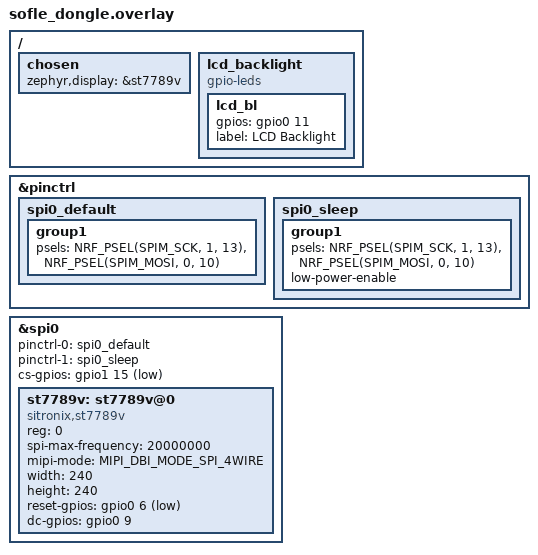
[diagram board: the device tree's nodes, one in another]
/*
 * Dongle Screen - ST7789 1.54" TFT SPI
 * Board: nice!nano / Pro Micro nRF52840
 *
 * Pinout:
 *   SCLK  -> P1.13 (D15)
 *   MOSI  -> P0.10 (D16)
 *   CS    -> P1.15 (D18)
 *   DC    -> P0.09 (D10)
 *   RST   -> P0.06 (D1)
 *   BL    -> P0.11 (D7)
 *   VCC   -> 3.3V
 *   GND   -> GND
 */

#include <zephyr/dt-bindings/gpio/gpio.h>
#include <zephyr/dt-bindings/mipi_dbi/mipi_dbi.h>

/ {
    chosen {
        zephyr,display = &st7789v;
    };

    /* Backlight como LED GPIO */
    lcd_backlight: lcd_backlight {
        compatible = "gpio-leds";
        lcd_bl: lcd_bl {
            gpios = <&gpio0 11 GPIO_ACTIVE_HIGH>;
            label = "LCD Backlight";
        };
    };
};

/* Configuración de pines SPI0 para nRF52840 */
&pinctrl {
    spi0_default: spi0_default {
        group1 {
            psels = <NRF_PSEL(SPIM_SCK, 1, 13)>,
                    <NRF_PSEL(SPIM_MOSI, 0, 10)>;
        };
    };

    spi0_sleep: spi0_sleep {
        group1 {
            psels = <NRF_PSEL(SPIM_SCK, 1, 13)>,
                    <NRF_PSEL(SPIM_MOSI, 0, 10)>;
            low-power-enable;
        };
    };
};

&spi0 {
    status = "okay";
    pinctrl-0 = <&spi0_default>;
    pinctrl-1 = <&spi0_sleep>;
    pinctrl-names = "default", "sleep";

    cs-gpios = <&gpio1 15 GPIO_ACTIVE_LOW>; /* CS en P1.15 */

    st7789v: st7789v@0 {
        compatible = "sitronix,st7789v";
        reg = <0>;
        spi-max-frequency = <20000000>;

        /* Requerido por Zephyr 4.1 */
        mipi-mode = "MIPI_DBI_MODE_SPI_4WIRE";

        /* Dimensiones de la pantalla */
        width = <240>;
        height = <240>;

        /* Pines de control */
        reset-gpios = <&gpio0 6 GPIO_ACTIVE_LOW>;   /* RST en P0.06 */
        dc-gpios    = <&gpio0 9 GPIO_ACTIVE_HIGH>;  /* DC  en P0.09 */

        /*
         * Si los colores salen invertidos (rojo <-> azul),
         * prueba a añadir una de estas líneas:
         *
         *   inversion-off;
         *
         * o ajustar el orden de color con mdac:
         *
         *   mdac = <0x08>;
         */
    };
};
